# SAMA7D65D4GN8 register map
Vendor: Microchip Technology; Series: SAMA7D6; File version: 0
Registers are 32-bit, read-write, reset 0x0 unless marked. A register's access mark holds for its fields unless they carry their own. Offsets are from the block's base; [hi:lo] are bit positions; {n}, {i} and the like mark numbered series; 'fields as' and 'values as' point back to an identical list.

## FLEXCOM0 (part 1 of 2) — Flexible Serial Communication
Base 0xE1820000; register names take the prefix FLEXCOM_
Same registers: FLEXCOM1 0xE1824000, FLEXCOM2 0xE1828000, FLEXCOM3 0xE182C000, FLEXCOM4 0xE2018000, FLEXCOM5 0xE201C000, FLEXCOM6 0xE2020000, FLEXCOM7 0xE2024000, FLEXCOM8 0xE281C000, FLEXCOM9 0xE2820000, FLEXCOM10 0xE2824000
0x00 FLEX_MR reset 0x1 — FLEXCOM Mode Register
  [1:0] OPMODE — FLEXCOM Operating Mode
    0=NO_COM (No communication); 1=USART (All UART related protocols are selected (RS232, RS485, IrDA, ISO7816, LIN,) SPI/TWI related registers are not accessible and have no impact on IOs.); 2=SPI (SPI operating mode is selected. USART/TWI related registers are not accessible and have no impact on IOs.); 3=TWI (All TWI related protocols are selected (TWI, SMBus). USART/SPI related registers are not accessible and have no impact on IOs.)
0x10 FLEX_RHR ro — FLEXCOM Receive Holding Register
  [15:0] RXDATA — Receive Data
0x20 FLEX_THR — FLEXCOM Transmit Holding Register
  [15:0] TXDATA — Transmit Data
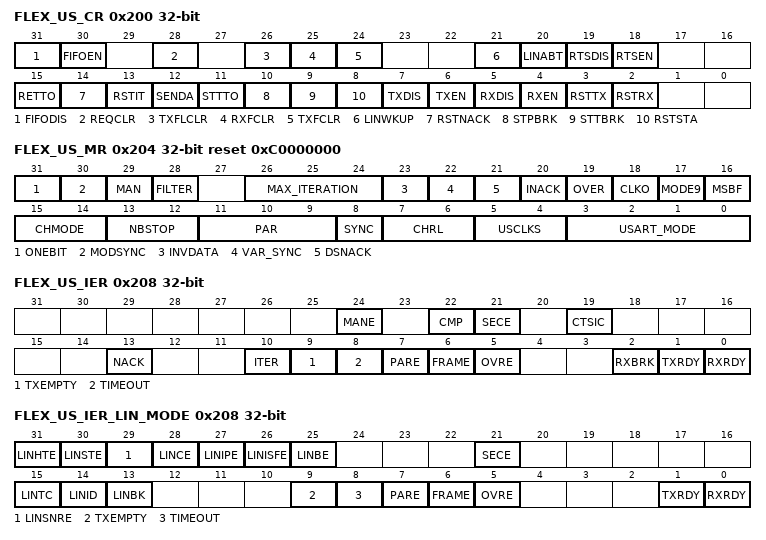
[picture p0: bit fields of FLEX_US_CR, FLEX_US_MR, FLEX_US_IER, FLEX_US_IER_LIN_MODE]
0x200 FLEX_US_CR wo — USART Control Register
  [31] FIFODIS — FIFO Disable
    0=No effect; 1=Disables the Transmit and Receive FIFOs
  [30] FIFOEN — FIFO Enable
    0=No effect; 1=Enables the Transmit and Receive FIFOs
  [28] REQCLR — Request to Clear the Comparison Trigger
    0=No effect; 1=Clears the potential clock request currently issued by USART, thus the potential system wake-up is cancelled. ; Restarts the comparison trigger to enable FLEX_US_RHR loading.
  [26] TXFLCLR — Transmit FIFO Lock CLEAR
    0=No effect; 1=Clears the Transmit FIFO Lock
  [25] RXFCLR — Receive FIFO Clear
    0=No effect; 1=Empties the Receive FIFO
  [24] TXFCLR — Transmit FIFO Clear
    0=No effect; 1=Empties the Transmit FIFO
  [21] LINWKUP — Send LIN Wake-up Signal
    0=No effect:; 1=Sends a wake-up signal on the LIN bus
  [20] LINABT — Abort LIN Transmission
    0=No effect; 1=Aborts the current LIN transmission
  [19] RTSDIS — Request to Send Disable
    0=No effect; 1=Drives the RTS pin to 0 if FLEX_US_MR.USART_MODE field = 2, else drives the RTS pin to 1 if FLEX_US_MR.USART_MODE field = 0
  [18] RTSEN — Request to Send Enable
    0=No effect; 1=Drives the RTS pin to 1 if FLEX_US_MR.USART_MODE field = 2, else drives the RTS pin to 0 if FLEX_US_MR.USART_MODE field = 0
  [15] RETTO — Start Timeout Immediately
    0=No effect; 1=Immediately restarts timeout period
  [14] RSTNACK — Reset Non Acknowledge
    0=No effect; 1=Resets FLEX_US_CSR.NACK
  [13] RSTIT — Reset Iterations
    0=No effect; 1=Resets FLEX_US_CSR.ITER. No effect if the ISO7816 is not enabled.
  [12] SENDA — Send Address
    0=No effect; 1=In Multidrop mode only, the next character written to FLEX_US_THR is sent with the address bit set
  [11] STTTO — Clear TIMEOUT Flag and Start Timeout After Next Character Received
    0=No effect; 1=Starts waiting for a character before clocking the timeout counter. Immediately disables a timeout period in progress. Resets the FLEX_US_CSR.TIMEOUT status bit.
  [10] STPBRK — Stop Break
    0=No effect; 1=Stops transmission of the break after a minimum of one character length and transmits a high level during 12-bit periods. No effect if no break is being transmitted.
  [9] STTBRK — Start Break
    0=No effect; 1=Starts transmission of a break after the characters present in FLEX_US_THR and the Transmit Shift Register have been transmitted. No effect if a break is already being transmitted.
  [8] RSTSTA — Reset Status Bits
    0=No effect; 1=Resets the status bits PARE, FRAME, OVRE, MANE, LINBE, LINISFE, LINIPE, LINCE, LINSNRE, LINSTE, LINHTE, LINID, LINTC, LINBK, CMP and RXBRK in FLEX_US_CSR. Also resets the status bits TXFEF, TXFFF, TXFTHF, RXFEF, RXFFF, RXFTHF, TXFPTEF, RXFPTEF in FLEX_US_FESR.
  [7] TXDIS — Transmitter Disable
    0=No effect; 1=Disables the transmitter
  [6] TXEN — Transmitter Enable
    0=No effect; 1=Enables the transmitter if TXDIS is 0
  [5] RXDIS — Receiver Disable
    0=No effect; 1=Disables the receiver
  [4] RXEN — Receiver Enable
    0=No effect; 1=Enables the receiver, if RXDIS is 0
  [3] RSTTX — Reset Transmitter
    0=No effect; 1=Resets the transmitter
  [2] RSTRX — Reset Receiver
    0=No effect; 1=Resets the receiver
0x204 FLEX_US_MR reset 0xC0000000 — USART Mode Register
  [31] ONEBIT — Start Frame Delimiter Selector
    0=Start frame delimiter is COMMAND or DATA SYNC; 1=Start frame delimiter is one bit
  [30] MODSYNC — Manchester Synchronization Mode
    0=The Manchester start bit is a 0 to 1 transition; 1=The Manchester start bit is a 1 to 0 transition
  [29] MAN — Manchester Encoder/Decoder Enable
    0=Manchester encoder/decoder are disabled; 1=Manchester encoder/decoder are enabled
  [28] FILTER — Receive Line Filter
    0=The USART does not filter the receive line; 1=The USART filters the receive line using a three-sample filter (1/16-bit clock) (2 over 3 majority)
  [26:24] MAX_ITERATION — Maximum Number of Automatic Iteration
  [23] INVDATA — Inverted Data
    0=The data field transmitted on TXD line is the same as the one written in FLEX_US_THR or the content read in FLEX_US_RHR is the same as RXD line. Normal mode of operation.; 1=The data field transmitted on TXD line is inverted (voltage polarity only) compared to the value written in FLEX_US_THR or the content read in FLEX_US_RHR is inverted compared to what is received on RXD line (or ISO7816 IO line). Inverted mode of operation, useful for contactless card application. To be used with configuration bit MSBF.
  [22] VAR_SYNC — Variable Synchronization of Command/Data Sync Start Frame Delimiter
    0=User defined configuration of command or data sync field depending on MODSYNC value; 1=The sync field is updated when a character is written into FLEX_US_THR
  [21] DSNACK — Disable Successive NACK
    0=NACK is sent on the ISO line as soon as a parity error occurs in the received character (unless INACK is set); 1=Successive parity errors are counted up to the value specified in the MAX_ITERATION field. These parity errors generate a NACK on the ISO line. As soon as this value is reached, no additional NACK is sent on the ISO line. The flag ITER is asserted.
  [20] INACK — Inhibit Non Acknowledge
    0=The NACK is generated; 1=The NACK is not generated
  [19] OVER — Oversampling Mode
    0=16x Oversampling; 1=8x Oversampling
  [18] CLKO — Clock Output Select
    0=The USART does not drive the SCK pin (Synchronous Client mode or Asynchronous mode with external baud rate clock source); 1=The USART drives the SCK pin if USCLKS does not select the external clock SCK (USART Synchronous Host mode)
  [17] MODE9 — 9-bit Character Length
    0=CHRL defines character length; 1=9-bit character length
  [16] MSBF — Bit Order
    0=Least significant bit is sent/received first; 1=Most significant bit is sent/received first
  [15:14] CHMODE — Channel Mode
    0=NORMAL (Normal mode); 1=AUTOMATIC (Automatic Echo. Receiver input is connected to the TXD pin.); 2=LOCAL_LOOPBACK (Local Loopback. Transmitter output is connected to the Receiver Input.); 3=REMOTE_LOOPBACK (Remote Loopback. RXD pin is internally connected to the TXD pin.)
  [13:12] NBSTOP — Number of Stop Bits
    0=1_BIT (1 stop bit); 1=1_5_BIT (1.5 stop bit (SYNC = 0) or reserved (SYNC = 1)); 2=2_BIT (2 stop bits)
  [11:9] PAR — Parity Type
    0=EVEN (Even parity); 1=ODD (Odd parity); 2=SPACE (Parity forced to 0 (Space)); 3=MARK (Parity forced to 1 (Mark)); 4=NO (No parity); 6=MULTIDROP (Multidrop mode)
  [8] SYNC — Synchronous Mode Select
    0=USART operates in Asynchronous mode (UART); 1=USART operates in Synchronous mode
  [7:6] CHRL — Character Length
    {v}={v+5}_BIT (Character length is {v+5} bits) (v=0..3)
  [5:4] USCLKS — Clock Selection
    0=MCK (Peripheral clock is selected); 2=GCLK (PMC generic clock is selected. If the SCK pin is driven (CLKO = 1), the CD field must be greater than 1.); 3=SCK (External pin SCK is selected)
  [3:0] USART_MODE — USART Mode of Operation
    0=NORMAL (Normal mode); 1=RS485; 2=HW_HANDSHAKING (Hardware handshaking); 4=ISO7816_T_0 (ISO7816 Protocol: T = 0); 6=ISO7816_T_1 (ISO7816 Protocol: T = 1); 8=IRDA; 10=LIN_MASTER (LIN Host mode); 11=LIN_SLAVE (LIN Client mode); 12=DATA16BIT_MASTER (16-bit data host); 13=DATA16BIT_SLAVE (16-bit data client)
0x208 FLEX_US_IER wo — USART Interrupt Enable Register
  [24] MANE — Manchester Error Interrupt Enable
  [22] CMP — Comparison Interrupt Enable
  [21] SECE — Security/Safety Error Interrupt Enable
  [19] CTSIC — Clear to Send Input Change Interrupt Enable
  [13] NACK — Non Acknowledge Interrupt Enable
  [10] ITER — Max number of Repetitions Reached Interrupt Enable
  [9] TXEMPTY — TXEMPTY Interrupt Enable
  [8] TIMEOUT — Timeout Interrupt Enable
  [7] PARE — Parity Error Interrupt Enable
  [6] FRAME — Framing Error Interrupt Enable
  [5] OVRE — Overrun Error Interrupt Enable
  [2] RXBRK — Receiver Break Interrupt Enable
  [1] TXRDY — TXRDY Interrupt Enable
  [0] RXRDY — RXRDY Interrupt Enable
0x208 FLEX_US_IER_LIN_MODE wo (alternate view of FLEX_US_IER) — USART Interrupt Enable Register
  [31] LINHTE — LIN Header Timeout Error Interrupt Enable
  [30] LINSTE — LIN Synch Tolerance Error Interrupt Enable
  [29] LINSNRE — LIN Client Not Responding Error Interrupt Enable
  [28] LINCE — LIN Checksum Error Interrupt Enable
  [27] LINIPE — LIN Identifier Parity Interrupt Enable
  [26] LINISFE — LIN Inconsistent Synch Field Error Interrupt Enable
  [25] LINBE — LIN Bus Error Interrupt Enable
  [21] SECE — Security/Safety Error Interrupt Enable
  [15] LINTC — LIN Transfer Completed Interrupt Enable
  [14] LINID — LIN Identifier Sent or LIN Identifier Received Interrupt Enable
  [13] LINBK — LIN Break Sent or LIN Break Received Interrupt Enable
  [9] TXEMPTY — TXEMPTY Interrupt Enable
  [8] TIMEOUT — Timeout Interrupt Enable
  [7] PARE — Parity Error Interrupt Enable
  [6] FRAME — Framing Error Interrupt Enable
  [5] OVRE — Overrun Error Interrupt Enable
  [1] TXRDY — TXRDY Interrupt Enable
  [0] RXRDY — RXRDY Interrupt Enable
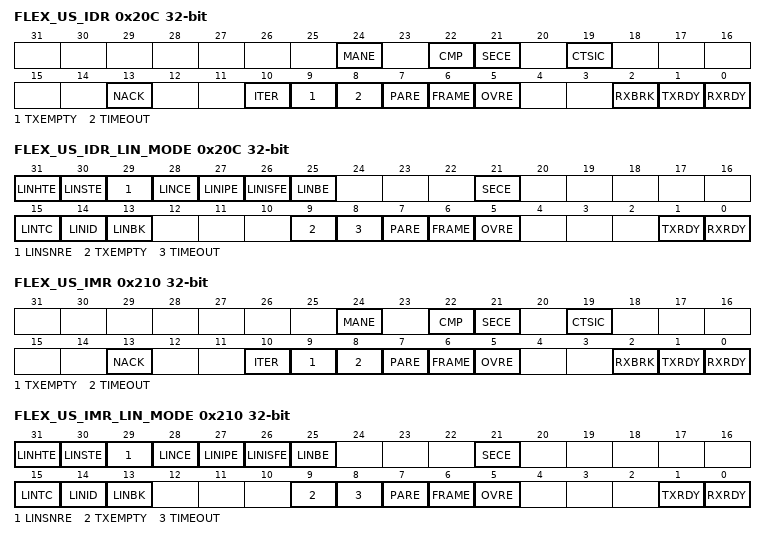
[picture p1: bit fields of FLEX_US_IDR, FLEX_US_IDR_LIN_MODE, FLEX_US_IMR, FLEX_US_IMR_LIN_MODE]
0x20C FLEX_US_IDR wo — USART Interrupt Disable Register
  [24] MANE — Manchester Error Interrupt Disable
  [22] CMP — Comparison Interrupt Disable
  [21] SECE — Security/Safety Error Interrupt Disable
  [19] CTSIC — Clear to Send Input Change Interrupt Disable
  [13] NACK — Non Acknowledge Interrupt Disable
  [10] ITER — Max Number of Repetitions Reached Interrupt Disable
  [9] TXEMPTY — TXEMPTY Interrupt Disable
  [8] TIMEOUT — Timeout Interrupt Disable
  [7] PARE — Parity Error Interrupt Disable
  [6] FRAME — Framing Error Interrupt Disable
  [5] OVRE — Overrun Error Interrupt Disable
  [2] RXBRK — Receiver Break Interrupt Disable
  [1] TXRDY — TXRDY Interrupt Disable
  [0] RXRDY — RXRDY Interrupt Disable
0x20C FLEX_US_IDR_LIN_MODE wo (alternate view of FLEX_US_IDR) — USART Interrupt Disable Register
  [31] LINHTE — LIN Header Timeout Error Interrupt Disable
  [30] LINSTE — LIN Synch Tolerance Error Interrupt Disable
  [29] LINSNRE — LIN Client Not Responding Error Interrupt Disable
  [28] LINCE — LIN Checksum Error Interrupt Disable
  [27] LINIPE — LIN Identifier Parity Interrupt Disable
  [26] LINISFE — LIN Inconsistent Synch Field Error Interrupt Disable
  [25] LINBE — LIN Bus Error Interrupt Disable
  [21] SECE — Security/Safety Error Interrupt Disable
  [15] LINTC — LIN Transfer Completed Interrupt Disable
  [14] LINID — LIN Identifier Sent or LIN Identifier Received Interrupt Disable
  [13] LINBK — LIN Break Sent or LIN Break Received Interrupt Disable
  [9] TXEMPTY — TXEMPTY Interrupt Disable
  [8] TIMEOUT — Timeout Interrupt Disable
  [7] PARE — Parity Error Interrupt Disable
  [6] FRAME — Framing Error Interrupt Disable
  [5] OVRE — Overrun Error Interrupt Disable
  [1] TXRDY — TXRDY Interrupt Disable
  [0] RXRDY — RXRDY Interrupt Disable
0x210 FLEX_US_IMR ro — USART Interrupt Mask Register
  [24] MANE — Manchester Error Interrupt Mask
  [22] CMP — Comparison Interrupt Mask
  [21] SECE — Security/Safety Error Interrupt Mask
  [19] CTSIC — Clear to Send Input Change Interrupt Mask
  [13] NACK — Non Acknowledge Interrupt Mask
  [10] ITER — Max Number of Repetitions Reached Interrupt Mask
  [9] TXEMPTY — TXEMPTY Interrupt Mask
  [8] TIMEOUT — Timeout Interrupt Mask
  [7] PARE — Parity Error Interrupt Mask
  [6] FRAME — Framing Error Interrupt Mask
  [5] OVRE — Overrun Error Interrupt Mask
  [2] RXBRK — Receiver Break Interrupt Mask
  [1] TXRDY — TXRDY Interrupt Mask
  [0] RXRDY — RXRDY Interrupt Mask
0x210 FLEX_US_IMR_LIN_MODE ro (alternate view of FLEX_US_IMR) — USART Interrupt Mask Register
  [31] LINHTE — LIN Header Timeout Error Interrupt Mask
  [30] LINSTE — LIN Synch Tolerance Error Interrupt Mask
  [29] LINSNRE — LIN Client Not Responding Error Interrupt Mask
  [28] LINCE — LIN Checksum Error Interrupt Mask
  [27] LINIPE — LIN Identifier Parity Interrupt Mask
  [26] LINISFE — LIN Inconsistent Synch Field Error Interrupt Mask
  [25] LINBE — LIN Bus Error Interrupt Mask
  [21] SECE — Security/Safety Error Interrupt mask
  [15] LINTC — LIN Transfer Completed Interrupt Mask
  [14] LINID — LIN Identifier Sent or LIN Identifier Received Interrupt Mask
  [13] LINBK — LIN Break Sent or LIN Break Received Interrupt Mask
  [9] TXEMPTY — TXEMPTY Interrupt Mask
  [8] TIMEOUT — Timeout Interrupt Mask
  [7] PARE — Parity Error Interrupt Mask
  [6] FRAME — Framing Error Interrupt Mask
  [5] OVRE — Overrun Error Interrupt Mask
  [1] TXRDY — TXRDY Interrupt Mask
  [0] RXRDY — RXRDY Interrupt Mask
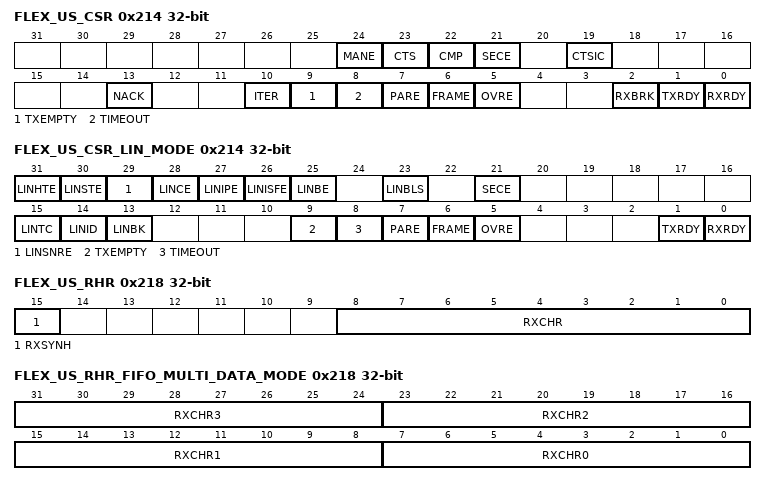
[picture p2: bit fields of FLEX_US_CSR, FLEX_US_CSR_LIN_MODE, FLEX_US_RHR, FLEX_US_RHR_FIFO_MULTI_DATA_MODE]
0x214 FLEX_US_CSR ro — USART Channel Status Register
  [24] MANE — Manchester Error
    0=No Manchester error has been detected since the last RSTSTA command was issued; 1=At least one Manchester error has been detected since the last RSTSTA command was issued
  [23] CTS — Image of CTS Input
    0=CTS input is driven low; 1=CTS input is driven high
  [22] CMP — Comparison Status
    0=No received character matched the comparison criteria programmed in VAL1, VAL2 fields and CMPPAR bit in since the last RSTSTA command was issued; 1=A received character matched the comparison criteria since the last RSTSTA command was issued
  [21] SECE — Security/Safety Error (cleared on read)
    0=No error detected on TXD and/or SCK pad output and no access violation of a write-protected register since the last read of FLEX_US_CSR; 1=An error has been detected on TXD and/or SCK pad output (FLEX_US_WPSR.PADERR=1) and/or a violation of a write-protected register (FLEX_US_WPSR.WPVS=1) since the last read of FLEX_US_CSR
  [19] CTSIC — Clear to Send Input Change Flag
    0=No input change has been detected on the CTS pin since the last read of FLEX_US_CSR; 1=At least one input change has been detected on the CTS pin since the last read of FLEX_US_CSR
  [13] NACK — Non Acknowledge Interrupt
    0=Non acknowledge has not been detected since the last RSTNACK; 1=At least one non acknowledge has been detected since the last RSTNACK
  [10] ITER — Max Number of Repetitions Reached
    0=Maximum number of repetitions has not been reached since the last RSTIT command was issued; 1=Maximum number of repetitions has been reached since the last RSTIT command was issued
  [9] TXEMPTY — Transmitter Empty (cleared by writing FLEX_US_THR)
    0=There are characters in either FLEX_US_THR or the Transmit Shift Register, or the transmitter is disabled; 1=There are no characters in FLEX_US_THR, nor in the Transmit Shift Register
  [8] TIMEOUT — Receiver Timeout
    0=There has not been a timeout since the last Start Timeout command (FLEX_US_CR.STTTO) or the Timeout Register is 0; 1=There has been a timeout since the last Start Timeout command (FLEX_US_CR.STTTO)
  [7] PARE — Parity Error
    0=No parity error has been detected since the last RSTSTA command was issued; 1=At least one parity error has been detected since the last RSTSTA command was issued
  [6] FRAME — Framing Error
    0=No stop bit has been detected low since the last RSTSTA command was issued; 1=At least one stop bit has been detected low since the last RSTSTA command was issued
  [5] OVRE — Overrun Error
    0=No overrun error has occurred since the last RSTSTA command was issued; 1=At least one overrun error has occurred since the last RSTSTA command was issued
  [2] RXBRK — Break Received/End of Break
    0=No break received or end of break detected since the last RSTSTA command was issued; 1=Break received or end of break detected since the last RSTSTA command was issued
  [1] TXRDY — Transmitter Ready (cleared by writing FLEX_US_THR)
    0=FIFO Disabled: A character in FLEX_US_THR is waiting to be transferred to the Transmit Shift Register, or an STTBRK command has been requested, or the transmitter is disabled. As soon as the transmitter is enabled, TXRDY becomes 1. FIFO Enabled: Transmit FIFO is full and cannot accept more data; 1=FIFO Disabled: There is no character in FLEX_US_THR. FIFO Enabled: Transmit FIFO is not full; one or more data can be written according to TXRDYM field configuration
  [0] RXRDY — Receiver Ready (cleared by reading FLEX_US_RHR)
    0=FIFO Disabled: No complete character has been received since the last read of FLEX_US_RHR or the receiver is disabled. If characters were received when the receiver was disabled, RXRDY changes to 1 when the receiver is enabled. FIFO Enabled: Receive FIFO is empty; no data to read; 1=FIFO Disabled: At least one complete character has been received and FLEX_US_RHR has not yet been read. FIFO Enabled: At least one unread data is in the Receive FIFO
0x214 FLEX_US_CSR_LIN_MODE ro (alternate view of FLEX_US_CSR) — USART Channel Status Register
  [31] LINHTE — LIN Header Timeout Error
    0=No LIN header timeout error has been detected since the last RSTSTA command was issued; 1=A LIN header timeout error has been detected since the last RSTSTA command was issued
  [30] LINSTE — LIN Synch Tolerance Error
    0=No LIN synch tolerance error has been detected since the last RSTSTA command was issued; 1=A LIN synch tolerance error has been detected since the last RSTSTA command was issued
  [29] LINSNRE — LIN Client Not Responding Error
    0=No LIN client not responding error has been detected since the last RSTSTA command was issued; 1=A LIN client not responding error has been detected since the last RSTSTA command was issued
  [28] LINCE — LIN Checksum Error
    0=No LIN checksum error has been detected since the last RSTSTA command was issued; 1=A LIN checksum error has been detected since the last RSTSTA command was issued
  [27] LINIPE — LIN Identifier Parity Error
    0=No LIN identifier parity error has been detected since the last RSTSTA command was issued; 1=A LIN identifier parity error has been detected since the last RSTSTA command was issued
  [26] LINISFE — LIN Inconsistent Synch Field Error
    0=No LIN inconsistent synch field error has been detected since the last RSTSTA; 1=The USART is configured as a client node and a LIN Inconsistent synch field error has been detected since the last RSTSTA command was issued
  [25] LINBE — LIN Bit Error
    0=No bit error has been detected since the last RSTSTA command was issued; 1=A bit error has been detected since the last RSTSTA command was issued
  [23] LINBLS — LIN Bus Line Status
    0=LIN bus line is set to 0; 1=LIN bus line is set to 1
  [21] SECE — Security/Safety Error (cleared on read)
    values as FLEX_US_CSR.SECE
  [15] LINTC — LIN Transfer Completed
    0=The USART is idle or a LIN transfer is ongoing; 1=A LIN transfer has been completed since the last RSTSTA command was issued
  [14] LINID — LIN Identifier Sent or LIN Identifier Received
    0=Host Mode: No LIN identifier has been sent since the last RSTSTA command was issued. Client Mode: No LIN identifier has been received since the last RSTSTA command was issued.; 1=Host Mode: At least one LIN identifier has been sent since the last RSTSTA command was issued. Client Mode: At least one LIN identifier has been received since the last RSTSTA.
  [13] LINBK — LIN Break Sent or LIN Break Received
    0=Host Mode: No LIN break has been sent since the last RSTSTA command was issued. Client Mode: No LIN break has received sent since the last RSTSTA command was issued.; 1=Host Mode: At least one LIN break has been sent since the last RSTSTA. Client Mode: At least one LIN break has been received since the last RSTSTA command was issued.
  [9] TXEMPTY — Transmitter Empty (cleared by writing FLEX_US_THR)
    values as FLEX_US_CSR.TXEMPTY
  [8] TIMEOUT — Receiver Timeout
    0=There has not been a timeout since the last start timeout command (FLEX_US_CR.STTTO) or the Timeout Register is 0; 1=There has been a timeout since the last start timeout command (FLEX_US_CR.STTTO)
  [7] PARE — Parity Error
    values as FLEX_US_CSR.PARE
  [6] FRAME — Framing Error
    values as FLEX_US_CSR.FRAME
  [5] OVRE — Overrun Error
    values as FLEX_US_CSR.OVRE
  [1] TXRDY — Transmitter Ready (cleared by writing FLEX_US_THR)
    0=A character in FLEX_US_THR is waiting to be transferred to the Transmit Shift Register, or the transmitter is disabled. As soon as the transmitter is enabled, TXRDY becomes 1.; 1=There is no character in FLEX_US_THR
  [0] RXRDY — Receiver Ready (cleared by reading FLEX_US_RHR)
    0=No complete character has been received since the last read of FLEX_US_RHR or the receiver is disabled. If characters were being received when the receiver was disabled, RXRDY changes to 1 when the receiver is enabled.; 1=At least one complete character has been received and FLEX_US_RHR has not yet been read
0x218 FLEX_US_RHR ro — USART Receive Holding Register
  [15] RXSYNH — Received Sync
    0=Last character received is a data; 1=Last character received is a command
  [8:0] RXCHR — Received Character
0x218 FLEX_US_RHR_FIFO_MULTI_DATA_MODE ro (alternate view of FLEX_US_RHR) — USART Receive Holding Register
  [8n+7:8n] RXCHR{n} (n=0..3) — Received Characters
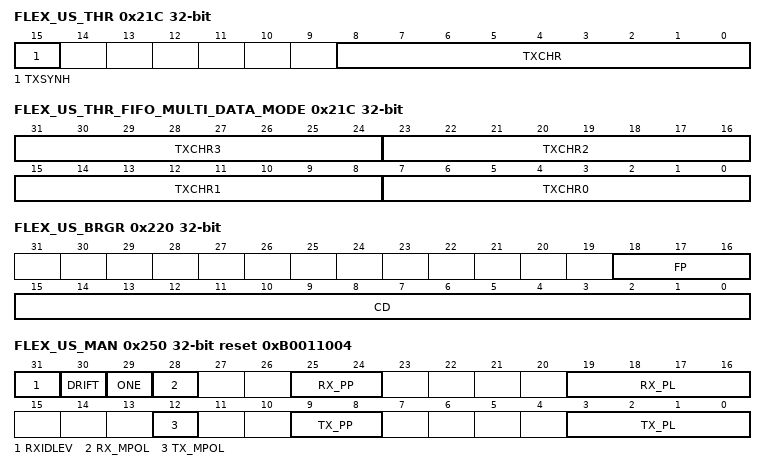
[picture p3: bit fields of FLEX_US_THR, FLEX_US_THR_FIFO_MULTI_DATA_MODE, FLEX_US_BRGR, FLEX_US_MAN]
0x21C FLEX_US_THR wo — USART Transmit Holding Register
  [15] TXSYNH — Sync Field to be Transmitted
    0=The next character sent is encoded as a data. Start frame delimiter is DATA SYNC.; 1=The next character sent is encoded as a command. Start frame delimiter is COMMAND SYNC.
  [8:0] TXCHR — Character to be Transmitted
0x21C FLEX_US_THR_FIFO_MULTI_DATA_MODE wo (alternate view of FLEX_US_THR) — USART Transmit Holding Register
  [8n+7:8n] TXCHR{n} (n=0..3) — Character to be Transmitted
0x220 FLEX_US_BRGR — USART Baud Rate Generator Register
  [18:16] FP — Fractional Part
    0=Fractional divider is disabled
  [15:0] CD — Clock Divider
0x224 FLEX_US_RTOR — USART Receiver Timeout Register
  [16:0] TO — Timeout Value
    0=The receiver timeout is disabled
0x228 FLEX_US_TTGR — USART Transmitter Timeguard Register
  [7:0] TG — Timeguard Value
    0=The transmitter timeguard is disabled
0x240 FLEX_US_FIDI reset 0x174 — USART FI DI Ratio Register
  [15:0] FI_DI_RATIO — FI Over DI Ratio Value
    0=If ISO7816 mode is selected, the baud rate generator generates no signal
0x244 FLEX_US_NER ro — USART Number of Errors Register
  [7:0] NB_ERRORS — Number of Errors
0x24C FLEX_US_IF — USART IrDA Filter Register
  [7:0] IRDA_FILTER
0x250 FLEX_US_MAN reset 0xB0011004 — USART Manchester Configuration Register
  [31] RXIDLEV — Receiver Idle Value
    0=Receiver line idle value is 0; 1=Receiver line idle value is 1
  [30] DRIFT — Drift Compensation
    0=The USART cannot recover from an important clock drift; 1=The USART can recover from clock drift. The 16X Clock mode must be enabled.
  [29] ONE — Must Be Set to 1
  [28] RX_MPOL — Receiver Manchester Polarity
    0=Logic zero is coded as a zero-to-one transition, Logic one is coded as a one-to-zero transition; 1=Logic zero is coded as a one-to-zero transition, Logic one is coded as a zero-to-one transition
  [25:24] RX_PP — Receiver Preamble Pattern detected
    0=ALL_ONE (The preamble is composed of '1's); 1=ALL_ZERO (The preamble is composed of '0's); 2=ZERO_ONE (The preamble is composed of '01's); 3=ONE_ZERO (The preamble is composed of '10's)
  [19:16] RX_PL — Receiver Preamble Length
    0=The receiver preamble pattern detection is disabled
  [12] TX_MPOL — Transmitter Manchester Polarity
    values as RX_MPOL
  [9:8] TX_PP — Transmitter Preamble Pattern
    values as RX_PP
  [3:0] TX_PL — Transmitter Preamble Length
    0=The transmitter preamble pattern generation is disabled
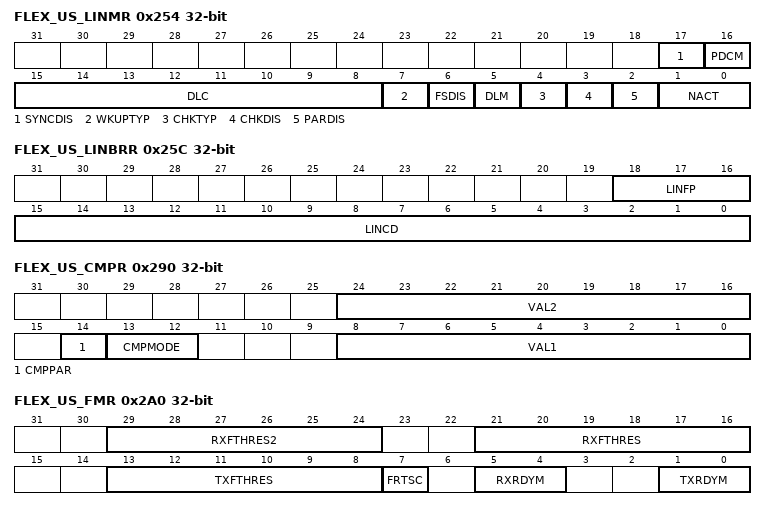
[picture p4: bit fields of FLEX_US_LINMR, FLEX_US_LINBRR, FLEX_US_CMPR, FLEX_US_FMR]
0x254 FLEX_US_LINMR — USART LIN Mode Register
  [17] SYNCDIS — Synchronization Disable
    0=The synchronization procedure is performed in LIN client node configuration; 1=The synchronization procedure is not performed in LIN client node configuration
  [16] PDCM — DMAC Mode
    0=The LIN mode register FLEX_US_LINMR is not written by the DMAC; 1=The LIN mode register FLEX_US_LINMR (excepting that flag) is written by the DMAC
  [15:8] DLC — Data Length Control
  [7] WKUPTYP — Wake-up Signal Type
    0=Setting the LINWKUP bit in the control register sends a LIN 2.0 wake-up signal; 1=Setting the LINWKUP bit in the control register sends a LIN 1.3 wake-up signal
  [6] FSDIS — Frame Slot Mode Disable
    0=The Frame Slot mode is enabled; 1=The Frame Slot mode is disabled
  [5] DLM — Data Length Mode
    0=The response data length is defined by the DLC field of this register; 1=The response data length is defined by the bits 5 and 6 of the identifier (FLEX_US_LINIR.IDCHR)
  [4] CHKTYP — Checksum Type
    0=LIN 2.0 'enhanced' checksum; 1=LIN 1.3 'classic' checksum
  [3] CHKDIS — Checksum Disable
    0=In host node configuration, the checksum is computed and sent automatically. In client node configuration, the checksum is checked automatically.; 1=Whatever the node configuration is, the checksum is not computed/sent and it is not checked
  [2] PARDIS — Parity Disable
    0=In host node configuration, the identifier parity is computed and sent automatically. In host node and client node configuration, the parity is checked automatically.; 1=Whatever the node configuration is, the Identifier parity is not computed/sent and it is not checked
  [1:0] NACT — LIN Node Action
    0=PUBLISH (The USART transmits the response.); 1=SUBSCRIBE (The USART receives the response.); 2=IGNORE (The USART does not transmit and does not receive the response.)
0x258 FLEX_US_LINIR — USART LIN Identifier Register
  [7:0] IDCHR — Identifier Character
0x25C FLEX_US_LINBRR ro — USART LIN Baud Rate Register
  [18:16] LINFP — Fractional Part after Synchronization
  [15:0] LINCD — Clock Divider after Synchronization
0x290 FLEX_US_CMPR — USART Comparison Register
  [24:16] VAL2 — Second Comparison Value for Received Character
  [14] CMPPAR — Compare Parity
    0=The parity is not checked and a bad parity cannot prevent from waking up the system; 1=The parity is checked and a matching condition on data can be cancelled by an error on parity bit, so no wake-up is performed
  [13:12] CMPMODE — Comparison Mode
    0=FLAG_ONLY (Any character is received and comparison function drives CMP flag.); 1=START_CONDITION (Comparison condition must be met to start reception.); 2=FILTER (Comparison must be met to receive the current data only)
  [8:0] VAL1 — First Comparison Value for Received Character
0x2A0 FLEX_US_FMR — USART FIFO Mode Register
  [29:24] RXFTHRES2 — Receive FIFO Threshold 2
  [21:16] RXFTHRES — Receive FIFO Threshold
  [13:8] TXFTHRES — Transmit FIFO Threshold
  [7] FRTSC — FIFO RTS Pin Control enable (Hardware Handshaking mode only)
    0=RTS pin is not controlled by Receive FIFO thresholds; 1=RTS pin is controlled by Receive FIFO thresholds
  [5:4] RXRDYM — Receiver Ready Mode
    0=ONE_DATA (RXRDY will be at level '1' when at least one unread data is in the receive FIFO. When DMA is enabled to transfer data and FLEX_US_MR.MODE9=0 (up to 8 bits to transfer on the line), the chunk of 1 byte must be configured in the DMA. If the transfer is performed by software, the access type must be defined as a byte.); 1=TWO_DATA (RXRDY will be at level '1' when at least two unread data are in the receive FIFO. To minimize system bus load, when DMA is enabled to transfer data and FLEX_US_MR.MODE9=0 (up to 8 bits to transfer on the line), the chunk of 1 halfword (1 halfword carries 2 bytes) must be configured in the DMA (chunk size=1 and halfword access). If the transfer is performed by software, the access type can be defined as byte (1 byte per access, 2 accesses) or halfword (2 bytes per access, 1 single access).); 2=FOUR_DATA (RXRDY will be at level '1' when at least four unread data are in the receive FIFO. To minimize system bus load, when DMA is enabled to transfer data and FLEX_US_MR.MODE9=0 (up to 8 bits to transfer on the line), the chunk of 1 word (1 word carries 4 bytes) must be configured in the DMA. If the transfer is performed by software, the access type can be defined as byte (1 byte per access, 4 accesses), halfword (2 bytes per access, 2 accesses) or word (4 bytes per access, 1 single access).); 3=EIGHT_DATA (RXRDY will be at level '1' when at least eight unread data are in the receive FIFO. To minimize system bus load, when DMA is enabled to transfer data and FLEX_US_MR.MODE9=0 (up to 8 bits transferred on the line), the chunk of 2 words (1 word carries 4 bytes) must be configured in the DMA (chunk size=2 and word access). If the transfer is performed by software, the access type can be defined as byte (1 byte per access, 8 accesses), halfword (2 bytes per access, 4 accesses) or word (4 bytes per access, 2 accesses).)
  [1:0] TXRDYM — Transmitter Ready Mode
    0=ONE_DATA (TXRDY will be at level '1' when at least one data can be written in the transmit FIFO. When DMA is enabled to transfer data and FLEX_US_MR.MODE9=0 (up to 8 bits to transfer on the line), the chunk of 1 byte must be configured in the DMA. If the transfer is performed by software, the access type must be defined as a byte.); 1=TWO_DATA (TXRDY will be at level '1' when at least two data can be written in the transmit FIFO. To minimize system bus load, when DMA is enabled to transfer data and FLEX_US_MR.MODE9=0 (up to 8 bits to transfer on the line), the chunk of 1 halfword (1 halfword carries 2 bytes) must be configured in the DMA. If the transfer is performed by software, the access type can be defined as byte (1 byte per access, 2 accesses) or halfword (2 bytes per access, 1 single access).); 2=FOUR_DATA (TXRDY will be at level '1' when at least four data can be written in the transmit FIFO. To minimize system bus load, when DMA is enabled to transfer data and FLEX_US_MR.MODE9=0 (up to 8 bits to transfer on the line), the chunk of 1 word (1 word carries 4 bytes) must be configured in the DMA (chunk size=1 and word access). If the transfer is performed by software, the access type can be defined as byte (1 byte per access, 4 accesses), halfword (2 bytes per access, 2 accesses) or word (4 bytes per access, 1 single access).); 3=EIGHT_DATA (TXRDY will be at level '1' when at least eight data can be written in the Transmit FIFO. To minimize system bus load, when DMA is enabled to transfer data and FLEX_US_MR.MODE9=0 (up to 8 bits transferred on the line), the chunk of 2 words (1 word carries 4 bytes) must be configured in the DMA (chunk size=2 and word access). If the transfer is performed by software, the access type can be defined as byte (1 byte per access, 8 accesses), halfword (2 bytes per access, 4 accesses) or word (4 bytes per access, 2 accesses).)
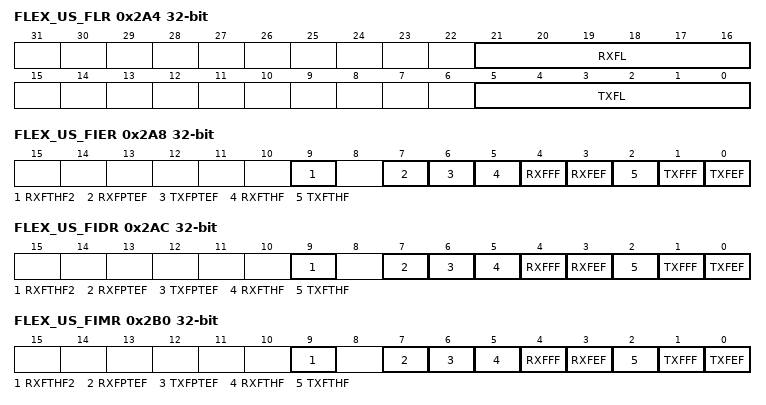
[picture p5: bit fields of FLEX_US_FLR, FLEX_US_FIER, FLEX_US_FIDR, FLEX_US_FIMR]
0x2A4 FLEX_US_FLR ro — USART FIFO Level Register
  [21:16] RXFL — Receive FIFO Level
    0=There is no unread data in the Receive FIFO
  [5:0] TXFL — Transmit FIFO Level
    0=There is no data in the Transmit FIFO
0x2A8 FLEX_US_FIER wo — USART FIFO Interrupt Enable Register
  [9] RXFTHF2 — RXFTHF2 Interrupt Enable
  [7] RXFPTEF — RXFPTEF Interrupt Enable
  [6] TXFPTEF — TXFPTEF Interrupt Enable
  [5] RXFTHF — RXFTHF Interrupt Enable
  [4] RXFFF — RXFFF Interrupt Enable
  [3] RXFEF — RXFEF Interrupt Enable
  [2] TXFTHF — TXFTHF Interrupt Enable
  [1] TXFFF — TXFFF Interrupt Enable
  [0] TXFEF — TXFEF Interrupt Enable
0x2AC FLEX_US_FIDR wo — USART FIFO Interrupt Disable Register
  [9] RXFTHF2 — RXFTHF2 Interrupt Disable
  [7] RXFPTEF — RXFPTEF Interrupt Disable
  [6] TXFPTEF — TXFPTEF Interrupt Disable
  [5] RXFTHF — RXFTHF Interrupt Disable
  [4] RXFFF — RXFFF Interrupt Disable
  [3] RXFEF — RXFEF Interrupt Disable
  [2] TXFTHF — TXFTHF Interrupt Disable
  [1] TXFFF — TXFFF Interrupt Disable
  [0] TXFEF — TXFEF Interrupt Disable
0x2B0 FLEX_US_FIMR ro — USART FIFO Interrupt Mask Register
  [9] RXFTHF2 — RXFTHF2 Interrupt Mask
  [7] RXFPTEF — RXFPTEF Interrupt Mask
  [6] TXFPTEF — TXFPTEF Interrupt Mask
  [5] RXFTHF — RXFTHF Interrupt Mask
  [4] RXFFF — RXFFF Interrupt Mask
  [3] RXFEF — RXFEF Interrupt Mask
  [2] TXFTHF — TXFTHF Interrupt Mask
  [1] TXFFF — TXFFF Interrupt Mask
  [0] TXFEF — TXFEF Interrupt Mask
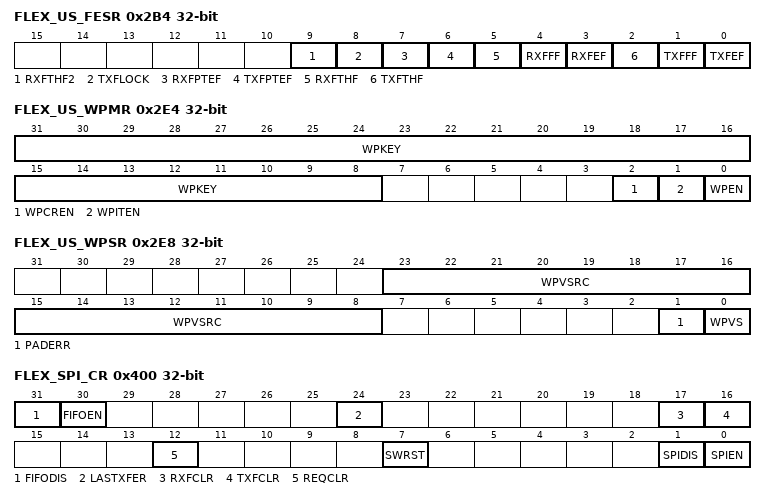
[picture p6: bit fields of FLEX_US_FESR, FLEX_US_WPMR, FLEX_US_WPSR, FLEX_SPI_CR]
0x2B4 FLEX_US_FESR ro — USART FIFO Event Status Register
  [9] RXFTHF2 — Receive FIFO Threshold Flag 2 (cleared by writing the FLEX_US_CR.RSTSTA bit)
    0=Number of unread data in Receive FIFO is above RXFTHRES threshold; 1=Number of unread data in Receive FIFO has reached RXFTHRES2 threshold since the last RSTSTA command was issued
  [8] TXFLOCK — Transmit FIFO Lock
    0=The Transmit FIFO is not locked; 1=The Transmit FIFO is locked
  [7] RXFPTEF — Receive FIFO Underflow Error Flag
    0=No Receive FIFO underflow occurred; 1=Receive FIFO underflow error occurred due to an incorrect software access (read data exceeding available data in FIFO). Receiver must be reset by writing FLEX_SPI_CR.SWRST=1.
  [6] TXFPTEF — Transmit FIFO Overflow Error Flag
    0=No Transmit FIFO overflow occurred; 1=Transmit FIFO overflow error occurred due to an incorrect software access (written data exceeding available space). Transceiver must be reset by writing FLEX_SPI_CR.SWRST=1.
  [5] RXFTHF — Receive FIFO Threshold Flag (cleared by writing the FLEX_US_CR.RSTSTA bit)
    0=Number of unread data in Receive FIFO is below RXFTHRES threshold; 1=Number of unread data in Receive FIFO has reached RXFTHRES threshold since the last RSTSTA command was issued
  [4] RXFFF — Receive FIFO Full Flag (cleared by writing the FLEX_US_CR.RSTSTA bit)
    0=Receive FIFO is not empty; 1=Receive FIFO has been filled since the last RSTSTA command was issued
  [3] RXFEF — Receive FIFO Empty Flag (cleared by writing the FLEX_US_CR.RSTSTA bit)
    0=Receive FIFO is not empty; 1=Receive FIFO has been emptied since the last RSTSTA command was issued
  [2] TXFTHF — Transmit FIFO Threshold Flag (cleared by writing the FLEX_US_CR.RSTSTA bit)
    0=Number of data in Transmit FIFO is above TXFTHRES threshold; 1=Number of data in Transmit FIFO has reached TXFTHRES threshold since the last RSTSTA command was issued
  [1] TXFFF — Transmit FIFO Full Flag (cleared by writing the FLEX_US_CR.RSTSTA bit)
    0=Transmit FIFO is not full; 1=Transmit FIFO has been filled since the last RSTSTA command was issued
  [0] TXFEF — Transmit FIFO Empty Flag (cleared by writing the FLEX_US_CR.RSTSTA bit)
    0=Transmit FIFO is not empty; 1=Transmit FIFO has been emptied since the last RSTSTA command was issued
0x2E4 FLEX_US_WPMR — USART Write Protection Mode Register
  [31:8] WPKEY — Write Protection Key
    0x555341=PASSWD (Writing any other value in this field aborts the write operation of bits WPEN, WPITEN and WPCREN. Always reads as 0.)
  [2] WPCREN — Write Protection Control Enable
    0=Disables the write protection on control register if WPKEY corresponds to 0x555341 ('USA' in ASCII); 1=Enables the write protection on control register if WPKEY corresponds to 0x555341 ('USA' in ASCII)
  [1] WPITEN — Write Protection Interrupt Enable
    0=Disables the write protection on interrupt registers if WPKEY corresponds to 0x555341 ('USA' in ASCII); 1=Enables the write protection on interrupt registers if WPKEY corresponds to 0x555341 ('USA' in ASCII)
  [0] WPEN — Write Protection Enable
    0=Disables the write protection on configuration registers if WPKEY corresponds to 0x555341 ('USA' in ASCII); 1=Enables the write protection on configuration registers if WPKEY corresponds to 0x555341 ('USA' in ASCII)
0x2E8 FLEX_US_WPSR ro — USART Write Protection Status Register
  [23:8] WPVSRC — Write Protection Violation Source
  [1] PADERR — Output PAD Error (cleared on read)
    0=No error detected during a character transfer; 1=Two successive bit period with a difference between the data read at the output of the TXD pad buffer and the input driven by USART or abnormal number of SCK edges (or no clock edge) at the output of SCK pad buffer in synchronous mode. This may be due to erroneous IO multiplexing configuration, external short circuits, etc.
  [0] WPVS — Write Protection Violation Status
    0=No write protection violation has occurred since the last read of FLEX_US_WPSR; 1=A write protection violation has occurred since the last read of FLEX_US_WPSR. If this violation is an unauthorized attempt to write a protected register, the associated violation is reported into field WPVSRC.
0x400 FLEX_SPI_CR wo — SPI Control Register
  [31] FIFODIS — FIFO Disable
    0=No effect; 1=Disables the Transmit and Receive FIFOs
  [30] FIFOEN — FIFO Enable
    0=No effect; 1=Enables the Transmit and Receive FIFOs
  [24] LASTXFER — Last Transfer
    0=No effect; 1=The current NPCS will be de-asserted after the character written in TD has been transferred. When CSAAT is set, the communication with the current serial peripheral can be closed by raising the corresponding NPCS line as soon as TD transfer is completed.
  [17] RXFCLR — Receive FIFO Clear
    0=No effect; 1=Empties the Receive FIFO
  [16] TXFCLR — Transmit FIFO Clear
    0=No effect; 1=Empties the Transmit FIFO
  [12] REQCLR — Request to Clear the Comparison Trigger
    0=No effect; 1=Asynchronous partial wakeup enabled: Clears the potential clock request currently issued by SPI, thus the potential system wake-up is cancelled. Asynchronous partial wakeup disabled: Restarts the comparison trigger to enable FLEX_SPI_RDR loading.
  [7] SWRST — SPI Software Reset
    0=No effect; 1=Reset the SPI. A software-triggered hardware reset of the SPI interface is performed.
  [1] SPIDIS — SPI Disable
    0=No effect; 1=Disables the SPI
  [0] SPIEN — SPI Enable
    0=No effect; 1=Enables the SPI to transfer and receive data
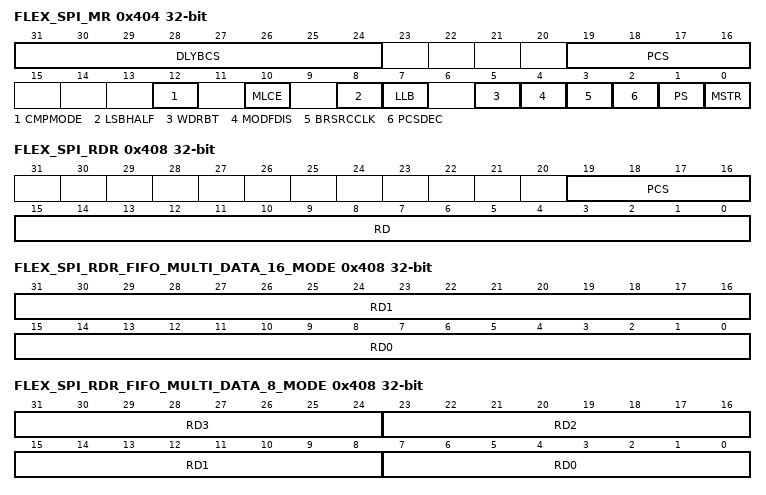
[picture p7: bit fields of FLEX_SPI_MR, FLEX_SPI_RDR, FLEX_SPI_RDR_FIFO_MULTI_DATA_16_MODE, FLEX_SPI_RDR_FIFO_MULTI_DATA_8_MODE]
0x404 FLEX_SPI_MR — SPI Mode Register
  [31:24] DLYBCS — Delay Between Chip Selects
  [19:16] PCS — Peripheral Chip Select
  [12] CMPMODE — Comparison Mode
    0=FLAG_ONLY (Any character is received and comparison function drives CMP flag.); 1=START_CONDITION (Comparison condition must be met to start reception of all incoming characters until REQCLR is set.)
  [10] MLCE — MOSI Line Check Enable
    0=Disables the MOSI line check; 1=Enables the MOSI line check during a character transfer
  [8] LSBHALF — Last Bit Half Period Compatibility
    0=Normal SPI mode of operation: all bits have a 1-bit time duration (standard SPI mode); 1=Compatibility mode when connected to an SPI client having only a half bit period duration time for the last bit of the frame (non-standard SPI mode)
  [7] LLB — Local Loopback Enable
    0=Local loopback path disabled; 1=Local loopback path enabled
  [5] WDRBT — Wait Data Read Before Transfer
    0=No Effect. In Host mode, a transfer can be initiated regardless of the FLEX_SPI_RDR state.; 1=In Host mode, a transfer can start only if FLEX_SPI_RDR is empty, i.e., does not contain any unread data. This mode prevents overrun error in reception.
  [4] MODFDIS — Mode Fault Detection
    0=Mode fault detection is enabled; 1=Mode fault detection is disabled
  [3] BRSRCCLK — Bit Rate Source Clock
    0=PERIPH_CLK (The peripheral clock is the source clock for the bit rate generation.); 1=GCLK (GCLK is the source clock for the bit rate generation, thus the bit rate can be independent of the core/peripheral clock.)
  [2] PCSDEC — Chip Select Decode
    0=The chip selects are directly connected to a peripheral device; 1=The four NPCS chip select lines are connected to a 4- to 16-bit decoder
  [1] PS — Peripheral Select
    0=Fixed Peripheral Select; 1=Variable Peripheral Select
  [0] MSTR — Host/Client Mode
    0=SPI is in Client mode; 1=SPI is in Host mode
0x408 FLEX_SPI_RDR ro — SPI Receive Data Register
  [19:16] PCS — Peripheral Chip Select
  [15:0] RD — Receive Data
0x408 FLEX_SPI_RDR_FIFO_MULTI_DATA_16_MODE ro (alternate view of FLEX_SPI_RDR) — SPI Receive Data Register
  [31:16] RD1 — Receive Data
  [15:0] RD0 — Receive Data
0x408 FLEX_SPI_RDR_FIFO_MULTI_DATA_8_MODE ro (alternate view of FLEX_SPI_RDR) — SPI Receive Data Register
  [8n+7:8n] RD{n} (n=0..3) — Receive Data
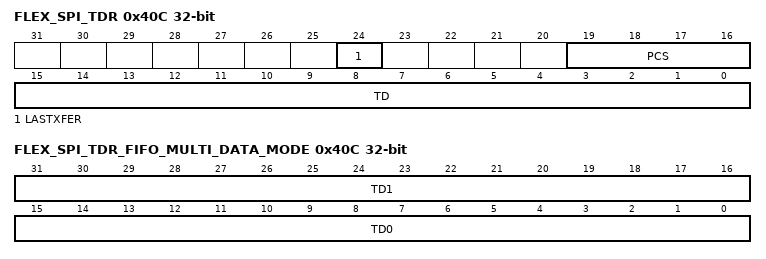
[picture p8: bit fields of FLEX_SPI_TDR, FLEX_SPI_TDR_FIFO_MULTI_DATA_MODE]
0x40C FLEX_SPI_TDR wo — SPI Transmit Data Register
  [24] LASTXFER — Last Transfer
    0=No effect; 1=The current NPCS is de-asserted after the transfer of the character written in TD. When FLEX_SPI_CSRx.CSAAT is set, the communication with the current serial peripheral can be closed by raising the corresponding NPCS line as soon as TD transfer is completed.
  [19:16] PCS — Peripheral Chip Select
  [15:0] TD — Transmit Data
0x40C FLEX_SPI_TDR_FIFO_MULTI_DATA_MODE wo (alternate view of FLEX_SPI_TDR) — SPI Transmit Data Register
  [31:16] TD1 — Transmit Data
  [15:0] TD0 — Transmit Data
